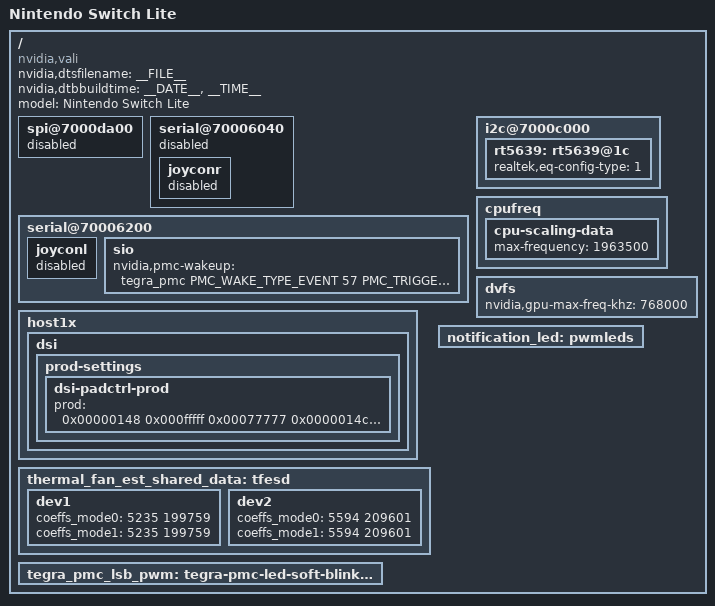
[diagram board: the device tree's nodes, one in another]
/*
 * Copyright (c) 2022, CTCaer <ctcaer@gmail.com>
 *
 * This program is free software; you can redistribute it and/or modify
 * it under the terms of the GNU General Public License as published by
 * the Free Software Foundation; version 2 of the License.
 *
 * This program is distributed in the hope that it will be useful, but WITHOUT
 * ANY WARRANTY; without even the implied warranty of MERCHANTABILITY or
 * FITNESS FOR A PARTICULAR PURPOSE.  See the GNU General Public License for
 * more details.
 *
 */

#include "nx-platforms/tegra210b01-nx-common.dtsi"
#include "nx-platforms/tegra210b01-vali-gpio.dtsi"
#include "nx-platforms/tegra210b01-vali-pinmux.dtsi"
#include "nx-platforms/tegra210-nx-common-disp.dtsi"
#include "nx-platforms/tegra210b01-vali-power-tree.dtsi"

/ {
	nvidia,dtsfilename = __FILE__;
	nvidia,dtbbuildtime = __DATE__, __TIME__;

	model = "Nintendo Switch Lite";
	compatible = "nvidia,vali", "nintendo,hoag", "nintendo,nx", "nvidia,tegra210b01";

	spi@7000da00 {
		status = "disabled"; /* Disabled for Vali since Sio uses it */
	};

	/* Right Joycon */
	serial@70006040 {
		status = "disabled";

		joyconr {
			status = "disabled";
		};
	};

	/* Left Joycon / Sio */
	serial@70006200 {
		status = "okay";
		/delete-property/ nvidia,invert-txd;
		/delete-property/ nvidia,invert-rts;

		joyconl {
			status = "disabled";
		};

		sio {
			status = "okay";

			nvidia,pmc-wakeup = <&tegra_pmc
					PMC_WAKE_TYPE_EVENT 57 PMC_TRIGGER_TYPE_LOW>; /* Sio HOME button (V, 3) */
		};
	};

	i2c@7000c000 {
		rt5639: rt5639@1c {
			realtek,eq-config-type = <1>;
		};
	};

	/* Do not actually disable, for having /sys/class/switch/dp/state. */
	host1x {
		/* tegradc.1: DP */
		/*
		dc@54240000 {
			status = "disabled";
		};

		sor1 {
			status = "disabled";
		};

		dpaux1 {
			status = "disabled";
		};
		*/

		dsi {
			prod-settings {
				#prod-cells = <3>;
				dsi-padctrl-prod {
					prod = <
						0x00000148 0x000fffff 0x00077777	/* PAD_CONTROL_4 */
						0x0000014c 0x000fffff 0x00077777	/* PAD_CONTROL_5 */
						0x00000150 0x00003333 0x00001111	/* PAD_CONTROL_6 */
						>;
				};
			};
		};
	};

	cpufreq {
		cpu-scaling-data {
			max-frequency = <1963500>;
		};
	};

	dvfs {
		nvidia,gpu-max-freq-khz = <768000>;
	};

	thermal_fan_est_shared_data: tfesd {
		dev1 {
			/* Vali SoC Console (Handheld) */
			coeffs_mode0 = <5235 199759>;

			/* Vali SoC Handheld */
			coeffs_mode1 = <5235 199759>;
		};

		dev2 {
			/* Vali PCB Console (Handheld) */
			coeffs_mode0 = <5594 209601>;

			/* Vali PCB Handheld */
			coeffs_mode1 = <5594 209601>;
		};
	};

	tegra_pmc_lsb_pwm: tegra-pmc-led-soft-blink-pwm {
		status = "okay";
	};

	notification_led: pwmleds {
		status = "okay";
	};
};
